# a34g43x register map
Vendor: ABOV Semiconductor Co., Ltd.; File version: 1.0
CPU: CM4 r0p1, little endian, MPU, FPU, VTOR, 4 interrupt priority bits
Registers are 32-bit, read-write, reset 0x0 unless marked. A register's access mark holds for its fields unless they carry their own. Offsets are from the block's base; [hi:lo] are bit positions; {n}, {i} and the like mark numbered series.

## UART — Universal Asynchronous Receiver/Transmitter
Base 0x50008000
Same registers: UART{n} {0x40008000+0x100*n} (n=0..12)
0x00 RBR ro — UARTn Receive Data Buffer Register
  [7:0] RBR — Receive buffer
0x00 THR wo — UARTn Transmit Data Hold Register
  [7:0] THR — Transmit buffer
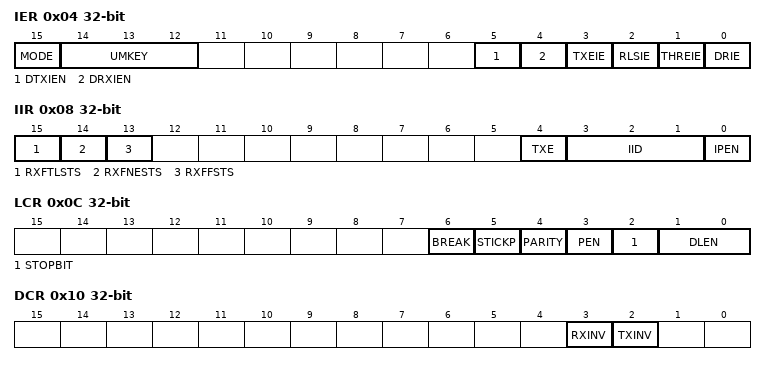
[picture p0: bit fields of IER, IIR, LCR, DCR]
0x04 IER — UARTn Interrupt Enable Register
  [15] MODE — UART mode selection bit
  [14:12] UMKEY wo — UART mode access key
  [5] DTXIEN — DMA Transmitter complete interrupt allow
  [4] DRXIEN — DMA Receiver over Interrupt allow
  [3] TXEIE — Transmit Empty Interrupt Enable bit
  [2] RLSIE — Receiver Line Status Interrupt Enable bit
  [1] THREIE — Transmit Holding Register Empty Interrupt Enable bit
  [0] DRIE — Data Receive Interrupt Enable bit
0x08 IIR ro — UARTn Interrupt ID Register
  [15] RXFTLSTS — Receive FIFO trigger level status
  [14] RXFNESTS — Receive FIFO not empty status
  [13] RXFFSTS — Receive FIFO full status
  [4] TXE — Transmit Complete Interrupt Source ID bit
  [3:1] IID — UARTn Interrupt ID bits. Note: The UARTn supports 3-priority interrupt generation and the interrupt source ID register shows one interrupt source which has highest priority among pending interrupts. The priority is defined as below. - Receive line status interrupt - Receive data ready interrupt and Character timeout interrupt - Transmit hold register empty interrupt
  [0] IPEN — Interrupt Pending bit
0x0C LCR — UARTn Line Control Register
  [6] BREAK — Transfer Break Control bit. The TXDn pin will be driven at low state in order to notice
  [5] STICKP — Force Parity bit. This bit is effective when the PEN bit is set to '1b'
  [4] PARITY — Parity Mode and Parity Stuck Selection bit
  [3] PEN — Parity Bit Transfer Enable bit
  [2] STOPBIT — Stop Bit Length Selection bit
  [1:0] DLEN — Data Length Selection bits
    {v}={v+5}bit data (v=0..3)
0x10 DCR — UARTn Data Control Register
  [3] RXINV — Rx Data Polarity selection
  [2] TXINV — Transmit Data Inversion Selection bit
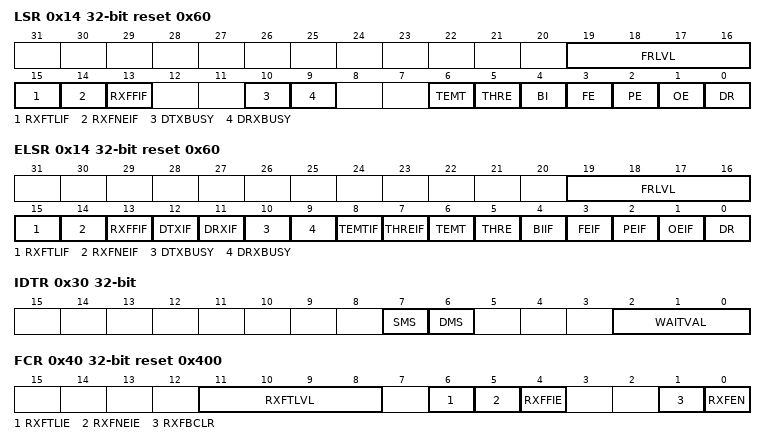
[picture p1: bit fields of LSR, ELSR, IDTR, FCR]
0x14 LSR reset 0x60 — UARTn Line Status Register
  [19:16] FRLVL ro — FIFO reception level
  [15] RXFTLIF — Receive FIFO trigger level interrupt flag
  [14] RXFNEIF — Receive FIFO not empty interrupt flag
  [13] RXFFIF — Receive FIFO full interrupt flag
  [10] DTXBUSY ro — DMA transmit busy check
  [9] DRXBUSY ro — DMA receive busy check
  [6] TEMT ro — Transmit Empty bit
  [5] THRE ro — Transmit Holding Empty bit. Note: This bit will be set to '1b' when it starts transmit.
  [4] BI ro — Break Condition Indication bit
  [3] FE ro — Frame Error Indicator bit
  [2] PE ro — Parity Error Indicator bit
  [1] OE ro — Overrun Error Indicator bit
  [0] DR ro — Data Receive Indicator bit
0x14 ELSR reset 0x60 (alternate view of LSR) — UARTn Line Status Register
  [19:16] FRLVL ro — FIFO reception level
  [15] RXFTLIF — Receive FIFO trigger level interrupt flag
  [14] RXFNEIF — Receive FIFO not empty interrupt flag
  [13] RXFFIF — Receive FIFO full interrupt flag
  [12] DTXIF — (Only Extended mode) DMA Transmit complete interrupt flag
  [11] DRXIF — (Only Extended mode) DMA Receive complete interrupt flag
  [10] DTXBUSY ro — DMA transmit busy check
  [9] DRXBUSY ro — DMA receive busy check
  [8] TEMTIF — (Only Extended mode) The transmit complete interrupt flag
  [7] THREIF — (Only Extended mode) The transmit data hold register empty interrupt flag
  [6] TEMT ro — Transmit Empty bit
  [5] THRE ro — Transmit Holding Empty bit. Note: This bit will be set to '1b' when it starts transmit.
  [4] BIIF ro — Break Condition Indication bit
  [3] FEIF ro — Frame Error Indicator bit
  [2] PEIF ro — Parity Error Indicator bit
  [1] OEIF ro — Overrun Error Indicator bit
  [0] DR ro — Data Receive Indicator bit
0x20 BDR — UARTn Baud Rate Divisor Latch Register
  [15:0] BDR — Baud Rate Divider Latch Value. Baud rate = fUARTnCLK/(16 x BDR[15:0] x 2). Note: The UART block won't work if the BDR[15:0] == 0x0000.
0x24 BFR — UARTn Baud Rate Fractional Counter Value
  [7:0] BFR — Fraction Counter value. 0 = Disable fraction counter N = Fraction compensation mode is operating. Fraction counter is incremented by FCNT. FCNT = Float * 256 Note: 8-bit fractional counter will count up by FCNT value every (baud rate)/16 period and whenever fractional counter overflow is happen, the divisor value will increment by 1. So this period will be compensated. Then next period, the divisor value will return to original set value.
0x30 IDTR — UARTn Inter-frame Delay Time Register
  [7] SMS — Start Bit Multi Sampling Enable bit
  [6] DMS — Data Bit Multi sampling enable
  [2:0] WAITVAL — Wait Time Value. Dummy delay can be inserted between 2 Continuous Transmits. Wait Time = WAITVAL[2:0]/(Baud Rate)
0x40 FCR reset 0x400 — UARTn FIFO Control Register
  [11:8] RXFTLVL — Receive FIFO trigger level selection bit
  [6] RXFTLIE — Enable or disable the Recevie FIFO trigger level interrupt
  [5] RXFNEIE — Enable or disable the Recevie FIFO not empty interrupt
  [4] RXFFIE — Enable or disable the Recevie FIFO full interrupt
  [1] RXFBCLR — Receive FIFO buffer clear bit. (Auto-clear)
  [0] RXFEN — Enable the Receive FIFO
0x44 FRBR ro — UARTn Recevie FIFO Register
  [16:0] FRBR — Receive FIFO Data Register
